# F28x7x_analog_subsys_regs register map
Vendor: Texas Instruments
Peripheral module from a debugger description file (folder C2000).
Address unit: 16 bits
Registers are 32-bit, read-write, no defined reset value unless marked. A register's access mark holds for its fields unless they carry their own. Offsets are as the file gives them; lines under a group give offsets from that group; [hi:lo] are bit positions; {n}, {i} and the like mark numbered series; 'fields as' and 'values as' point back to an identical list; <NAME> marks a mode.

## ANALOG_SUBSYS_REGS — ANALOG SUBSYS Registers
0x20 INTOSC1TRIM — Internal Oscillator 1 Trim Register
  [11:0] VALFINETRIM — Oscillator Value Fine Trim Bits
0x22 INTOSC2TRIM — Internal Oscillator 2 Trim Register
  [11:0] VALFINETRIM — Oscillator Value Fine Trim Bits
0x26 TSNSCTL 16-bit — Temperature Sensor Control Register
  [0] ENABLE — Temperature Sensor Enable
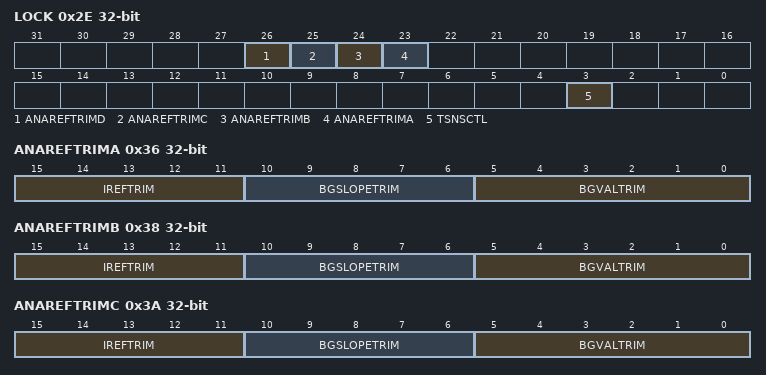
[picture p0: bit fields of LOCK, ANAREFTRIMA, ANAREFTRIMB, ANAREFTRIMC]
0x2E LOCK
  [26] ANAREFTRIMD — Analog Reference D Trim Register Lock
  [25] ANAREFTRIMC — Analog Reference C Trim Register Lock
  [24] ANAREFTRIMB — Analog Reference B Trim Register Lock
  [23] ANAREFTRIMA — Analog Reference A Trim Register Lock
  [3] TSNSCTL — Temperature Sensor Control Register Lock
0x36 ANAREFTRIMA — Analog Reference Trim A Register
  [15:11] IREFTRIM — Reference Current Trim
  [10:6] BGSLOPETRIM — Bandgap Slope Trim
  [5:0] BGVALTRIM — Bandgap Value Trim
0x38 ANAREFTRIMB — Analog Reference Trim B Register
  fields as ANAREFTRIMA
0x3A ANAREFTRIMC — Analog Reference Trim C Register
  fields as ANAREFTRIMA
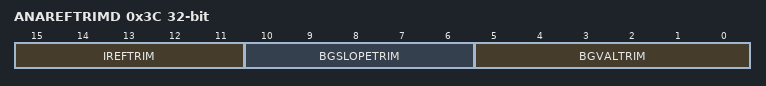
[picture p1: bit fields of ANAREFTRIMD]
0x3C ANAREFTRIMD — Analog Reference Trim D Register
  fields as ANAREFTRIMA
